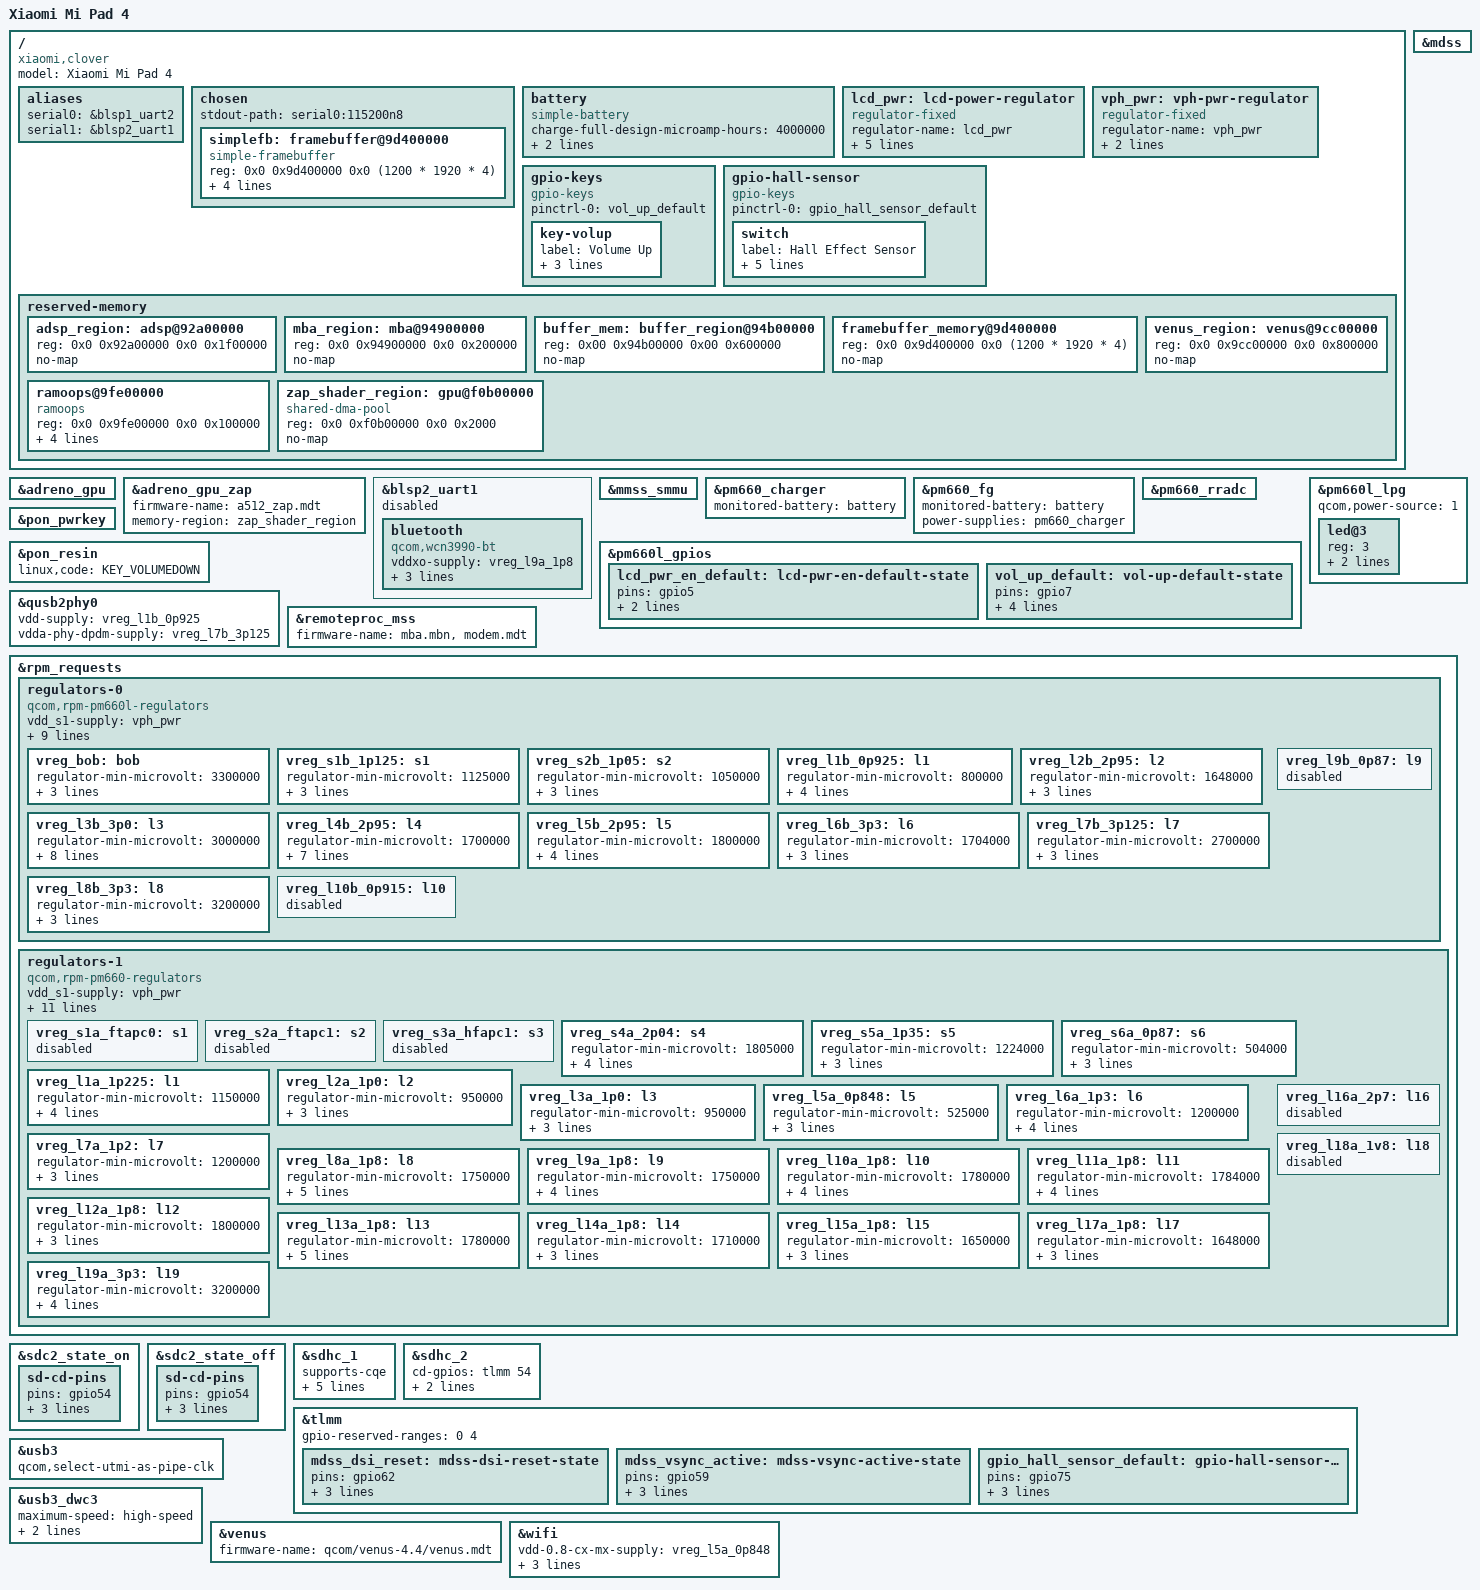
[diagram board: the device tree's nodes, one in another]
// SPDX-License-Identifier: GPL-2.0-only
/*
 * Copyright (c) 2020, Mark Hargreaves <clashclanacc2602@gmail.com>
 */

/dts-v1/;
#include "sdm660.dtsi"
#include "pm660.dtsi"
#include "pm660l.dtsi"
#include <dt-bindings/input/input.h>
#include <dt-bindings/input/gpio-keys.h>
#include <dt-bindings/leds/common.h>
#include <dt-bindings/pinctrl/qcom,pmic-gpio.h>

/delete-node/ &adsp_region;
/delete-node/ &buffer_mem;
/delete-node/ &mba_region;
/delete-node/ &zap_shader_region;
/delete-node/ &venus_region;

/ {
	/*
	 * This DT does not handle differences between Mi PAD 4 and Mi PAD 4 PLUS.
	 * This is commonized DTS contaning only subset of features between both
	 * xiaomi-clover and xiaomi-clover-plus needed for u-boot to function.
	 */
	model = "Xiaomi Mi Pad 4";
	compatible = "xiaomi,clover", "qcom,sdm660";

	aliases {
		serial0 = &blsp1_uart2; /* Debug UART */
		serial1 = &blsp2_uart1; /* Bluetooth UART */
	};

	chosen {
		#address-cells = <2>;
		#size-cells = <2>;
		ranges;

		stdout-path = "serial0:115200n8";

		/*
		 * Despite screen physical size is different between clover and
		 * clover-plus, the resolution is the same.
		 */
		simplefb: framebuffer@9d400000 {
			compatible = "simple-framebuffer";
			reg = <0x0 0x9d400000 0x0 (1200 * 1920 * 4)>;
			width = <1200>;
			height = <1920>;
			stride = <(1200 * 4)>;
			format = "a8r8g8b8";
		};
	};

	battery: battery {
		compatible = "simple-battery";

		charge-full-design-microamp-hours = <4000000>;
		voltage-min-design-microvolt = <3400000>;
		voltage-max-design-microvolt = <4408000>;
	};

	lcd_pwr: lcd-power-regulator {
		compatible = "regulator-fixed";
		regulator-name = "lcd_pwr";
		regulator-min-microvolt = <3300000>;
		regulator-max-microvolt = <3300000>;
		gpio = <&pm660l_gpios 5 GPIO_ACTIVE_HIGH>;
		enable-active-high;
		pinctrl-0 = <&lcd_pwr_en_default>;
		pinctrl-names = "default";
	};

	vph_pwr: vph-pwr-regulator {
		compatible = "regulator-fixed";
		regulator-name = "vph_pwr";

		regulator-always-on;
		regulator-boot-on;
	};

	gpio-keys {
		compatible = "gpio-keys";

		pinctrl-0 = <&vol_up_default>;
		pinctrl-names = "default";

		key-volup {
			label = "Volume Up";
			gpios = <&pm660l_gpios 7 GPIO_ACTIVE_LOW>;
			linux,code = <KEY_VOLUMEUP>;
			debounce-interval = <15>;
		};
	};

	gpio-hall-sensor {
		compatible = "gpio-keys";

		pinctrl-0 = <&gpio_hall_sensor_default>;
		pinctrl-names = "default";

		switch {
			label = "Hall Effect Sensor";
			gpios = <&tlmm 75 GPIO_ACTIVE_LOW>;
			linux,input-type = <EV_SW>;
			linux,code = <SW_LID>;
			linux,can-disable;
			wakeup-source;
		};
	};

	reserved-memory {
		#address-cells = <2>;
		#size-cells = <2>;
		ranges;

		adsp_region: adsp@92a00000 {
			reg = <0x0 0x92a00000 0x0 0x1f00000>;
			no-map;
		};

		mba_region: mba@94900000 {
			reg = <0x0 0x94900000 0x0 0x200000>;
			no-map;
		};

		buffer_mem: buffer_region@94b00000 {
			reg = <0x00 0x94b00000 0x00 0x600000>;
			no-map;
		};

		framebuffer_memory@9d400000 {
			reg = <0x0 0x9d400000 0x0 (1200 * 1920 * 4)>;
			no-map;
		};

		venus_region: venus@9cc00000 {
			reg = <0x0 0x9cc00000 0x0 0x800000>;
			no-map;
		};

		ramoops@9fe00000 {
			compatible = "ramoops";
			reg = <0x0 0x9fe00000 0x0 0x100000>;
			console-size = <0x80000>;
			record-size = <0x1000>;
			ftrace-size = <0x1000>;
			pmsg-size = <0x8000>;
		};

		zap_shader_region: gpu@f0b00000 {
			compatible = "shared-dma-pool";
			reg = <0x0 0xf0b00000 0x0 0x2000>;
			no-map;
		};

	};
};

&adreno_gpu {
	status = "okay";
};

&adreno_gpu_zap {
	firmware-name = "a512_zap.mdt";
	memory-region = <&zap_shader_region>;
};

&blsp2_uart1 {
	/* status = "okay"; Do not enable bluetooth UART, this confuses U-Boot */
	/* we build u-boot for clover without CONFIG_SERIAL_PRESENT */
	status = "disabled";

	bluetooth {
		compatible = "qcom,wcn3990-bt";
		vddxo-supply = <&vreg_l9a_1p8>;
		vddrf-supply = <&vreg_l6a_1p3>;
		vddch0-supply = <&vreg_l19a_3p3>;
		max-speed = <3200000>;
	};
};

&mdss {
	status = "okay";
};

&mmss_smmu {
	status = "okay";
};

&pm660_charger {
	monitored-battery = <&battery>;

	status = "okay";
};

&pm660_fg {
	monitored-battery = <&battery>;
	power-supplies = <&pm660_charger>;

	status = "okay";
};

&pm660_rradc {
	status = "okay";
};

&pm660l_gpios {
	lcd_pwr_en_default: lcd-pwr-en-default-state {
		pins = "gpio5";
		function = PMIC_GPIO_FUNC_NORMAL;
		bias-disable;
	};

	vol_up_default: vol-up-default-state {
		pins = "gpio7";
		function = PMIC_GPIO_FUNC_NORMAL;
		bias-pull-up;
		input-enable;
		qcom,drive-strength = <PMIC_GPIO_STRENGTH_NO>;
	};
};

&pm660l_lpg {
	qcom,power-source = <1>;

	status = "okay";

	#address-cells = <1>;
	#size-cells = <0>;

	led@3 {
		reg = <3>;
		color = <LED_COLOR_ID_WHITE>;
		function = LED_FUNCTION_STATUS;
	};
};

&pon_pwrkey {
	status = "okay";
};

&pon_resin {
	linux,code = <KEY_VOLUMEDOWN>;

	status = "okay";
};

&qusb2phy0 {
	vdd-supply = <&vreg_l1b_0p925>;
	vdda-phy-dpdm-supply = <&vreg_l7b_3p125>;

	status = "okay";
};

&remoteproc_mss {
	firmware-name = "mba.mbn", "modem.mdt";

	status = "okay";
};

&rpm_requests {
	regulators-0 {
		compatible = "qcom,rpm-pm660l-regulators";

		vdd_s1-supply = <&vph_pwr>;
		vdd_s2-supply = <&vph_pwr>;
		vdd_s3_s4-supply = <&vph_pwr>;
		vdd_s5-supply = <&vph_pwr>;
		vdd_s6-supply = <&vph_pwr>;

		vdd_l1_l9_l10-supply = <&vreg_s2b_1p05>;
		vdd_l2-supply = <&vreg_bob>;
		vdd_l3_l5_l7_l8-supply = <&vreg_bob>;
		vdd_l4_l6-supply = <&vreg_bob>;
		vdd_bob-supply = <&vph_pwr>;

		vreg_bob: bob {
			regulator-min-microvolt = <3300000>;
			regulator-max-microvolt = <3600000>;
			regulator-enable-ramp-delay = <500>;
			regulator-ramp-delay = <0>;
		};

		vreg_s1b_1p125: s1 {
			regulator-min-microvolt = <1125000>;
			regulator-max-microvolt = <1125000>;
			regulator-enable-ramp-delay = <200>;
			regulator-ramp-delay = <0>;
		};

		vreg_s2b_1p05: s2 {
			regulator-min-microvolt = <1050000>;
			regulator-max-microvolt = <1050000>;
			regulator-enable-ramp-delay = <200>;
			regulator-ramp-delay = <0>;
		};

		/* LDOs */
		vreg_l1b_0p925: l1 {
			regulator-min-microvolt = <800000>;
			regulator-max-microvolt = <925000>;
			regulator-enable-ramp-delay = <250>;
			regulator-ramp-delay = <0>;
			regulator-allow-set-load;
		};

		/* SDHCI 3.3V signal doesn't seem to be supported. */
		vreg_l2b_2p95: l2 {
			regulator-min-microvolt = <1648000>;
			regulator-max-microvolt = <3100000>;
			regulator-enable-ramp-delay = <250>;
			regulator-allow-set-load;
		};

		vreg_l3b_3p0: l3 {
			regulator-min-microvolt = <3000000>;
			regulator-max-microvolt = <3000000>;
			regulator-enable-ramp-delay = <250>;
			regulator-ramp-delay = <0>;
			regulator-min-microamp = <200>;
			regulator-max-microamp = <600000>;
			regulator-system-load = <100000>;
			regulator-allow-set-load;
			regulator-always-on;
		};

		vreg_l4b_2p95: l4 {
			regulator-min-microvolt = <1700000>;
			regulator-max-microvolt = <2952000>;
			regulator-enable-ramp-delay = <250>;
			regulator-ramp-delay = <0>;

			regulator-min-microamp = <200>;
			regulator-max-microamp = <600000>;
			regulator-system-load = <570000>;
			regulator-allow-set-load;
		};

		/*
		 * Downstream specifies a range of 1721-3600mV,
		 * but the only assigned consumers are SDHCI2 VMMC
		 * and Coresight QPDI that both request pinned 2.95V.
		 * Tighten the range to 1.8-3.328 (closest to 3.3) to
		 * make the mmc driver happy.
		 */
		vreg_l5b_2p95: l5 {
			regulator-min-microvolt = <1800000>;
			regulator-max-microvolt = <3328000>;
			regulator-enable-ramp-delay = <250>;
			regulator-ramp-delay = <0>;
			regulator-allow-set-load;
		};

		vreg_l6b_3p3: l6 {
			regulator-min-microvolt = <1704000>;
			regulator-max-microvolt = <3312000>;
			regulator-enable-ramp-delay = <250>;
			regulator-ramp-delay = <0>;
		};

		vreg_l7b_3p125: l7 {
			regulator-min-microvolt = <2700000>;
			regulator-max-microvolt = <3125000>;
			regulator-enable-ramp-delay = <250>;
			regulator-ramp-delay = <0>;
		};

		vreg_l8b_3p3: l8 {
			regulator-min-microvolt = <3200000>;
			regulator-max-microvolt = <3400000>;
			regulator-enable-ramp-delay = <250>;
			regulator-ramp-delay = <0>;
		};

		vreg_l9b_0p87: l9 {
			/* Unused */
			status = "disabled";
		};

		vreg_l10b_0p915: l10 {
			/* Unused */
			status = "disabled";
		};
	};

	regulators-1 {
		compatible = "qcom,rpm-pm660-regulators";

		vdd_s1-supply = <&vph_pwr>;
		vdd_s2-supply = <&vph_pwr>;
		vdd_s3-supply = <&vph_pwr>;
		vdd_s4-supply = <&vph_pwr>;
		vdd_s5-supply = <&vph_pwr>;
		vdd_s6-supply = <&vph_pwr>;

		vdd_l1_l6_l7-supply = <&vreg_s5a_1p35>;
		vdd_l2_l3-supply = <&vreg_s2b_1p05>;
		vdd_l5-supply = <&vreg_s2b_1p05>;
		vdd_l8_l9_l10_l11_l12_l13_l14-supply = <&vreg_s4a_2p04>;
		vdd_l15_l16_l17_l18_l19-supply = <&vreg_bob>;

		vreg_s1a_ftapc0: s1 {
			/* Unused */
			status = "disabled";
		};

		vreg_s2a_ftapc1: s2 {
			/* Unused */
			status = "disabled";
		};

		vreg_s3a_hfapc1: s3 {
			/* Unused */
			status = "disabled";
		};

		vreg_s4a_2p04: s4 {
			regulator-min-microvolt = <1805000>;
			regulator-max-microvolt = <2040000>;
			regulator-enable-ramp-delay = <200>;
			regulator-ramp-delay = <0>;
			regulator-always-on;
		};

		vreg_s5a_1p35: s5 {
			regulator-min-microvolt = <1224000>;
			regulator-max-microvolt = <1350000>;
			regulator-enable-ramp-delay = <200>;
			regulator-ramp-delay = <0>;
		};

		vreg_s6a_0p87: s6 {
			regulator-min-microvolt = <504000>;
			regulator-max-microvolt = <992000>;
			regulator-enable-ramp-delay = <150>;
			regulator-ramp-delay = <0>;
		};

		/* LDOs */
		vreg_l1a_1p225: l1 {
			regulator-min-microvolt = <1150000>;
			regulator-max-microvolt = <1250000>;
			regulator-enable-ramp-delay = <250>;
			regulator-ramp-delay = <0>;
			regulator-allow-set-load;
			/* regulator-always-on; */
		};

		vreg_l2a_1p0: l2 {
			regulator-min-microvolt = <950000>;
			regulator-max-microvolt = <1010000>;
			regulator-enable-ramp-delay = <250>;
			regulator-ramp-delay = <0>;
		};

		vreg_l3a_1p0: l3 {
			regulator-min-microvolt = <950000>;
			regulator-max-microvolt = <1010000>;
			regulator-enable-ramp-delay = <250>;
			regulator-ramp-delay = <0>;
		};

		vreg_l5a_0p848: l5 {
			regulator-min-microvolt = <525000>;
			regulator-max-microvolt = <952000>;
			regulator-enable-ramp-delay = <250>;
			regulator-ramp-delay = <0>;
		};

		vreg_l6a_1p3: l6 {
			regulator-min-microvolt = <1200000>;
			regulator-max-microvolt = <1368000>;
			regulator-allow-set-load;
			regulator-enable-ramp-delay = <250>;
			regulator-ramp-delay = <0>;
		};

		vreg_l7a_1p2: l7 {
			regulator-min-microvolt = <1200000>;
			regulator-max-microvolt = <1200000>;
			regulator-enable-ramp-delay = <250>;
			regulator-ramp-delay = <0>;
		};

		vreg_l8a_1p8: l8 {
			regulator-min-microvolt = <1750000>;
			regulator-max-microvolt = <1900000>;
			regulator-enable-ramp-delay = <250>;
			regulator-ramp-delay = <0>;
			regulator-system-load = <325000>;
			regulator-allow-set-load;
		};


		vreg_l9a_1p8: l9 {
			regulator-min-microvolt = <1750000>;
			regulator-max-microvolt = <1900000>;
			regulator-enable-ramp-delay = <250>;
			regulator-ramp-delay = <0>;
			regulator-allow-set-load;
		};

		vreg_l10a_1p8: l10 {
			regulator-min-microvolt = <1780000>;
			regulator-max-microvolt = <1950000>;
			regulator-enable-ramp-delay = <250>;
			regulator-ramp-delay = <0>;
			regulator-allow-set-load;
		};

		vreg_l11a_1p8: l11 {
			regulator-min-microvolt = <1784000>;
			regulator-max-microvolt = <1944000>;
			regulator-enable-ramp-delay = <250>;
			regulator-ramp-delay = <0>;
			regulator-always-on;
		};

		vreg_l12a_1p8: l12 {
			regulator-min-microvolt = <1800000>;
			regulator-max-microvolt = <1944000>;
			regulator-enable-ramp-delay = <250>;
			regulator-ramp-delay = <0>;
		};

		/* This gives power to the LPDDR4: never turn it off! */
		vreg_l13a_1p8: l13 {
			regulator-min-microvolt = <1780000>;
			regulator-max-microvolt = <1950000>;
			regulator-enable-ramp-delay = <250>;
			regulator-ramp-delay = <0>;
			regulator-boot-on;
			regulator-always-on;
		};

		vreg_l14a_1p8: l14 {
			regulator-min-microvolt = <1710000>;
			regulator-max-microvolt = <1904000>;
			regulator-enable-ramp-delay = <250>;
			regulator-ramp-delay = <0>;
		};

		vreg_l15a_1p8: l15 {
			regulator-min-microvolt = <1650000>;
			regulator-max-microvolt = <2952000>;
			regulator-enable-ramp-delay = <250>;
			regulator-ramp-delay = <0>;
		};

		vreg_l16a_2p7: l16 {
			/* Unused */
			status = "disabled";
		};

		vreg_l17a_1p8: l17 {
			regulator-min-microvolt = <1648000>;
			regulator-max-microvolt = <2952000>;
			regulator-enable-ramp-delay = <250>;
			regulator-ramp-delay = <0>;
		};

		vreg_l18a_1v8: l18 {
			status = "disabled";
		};

		vreg_l19a_3p3: l19 {
			regulator-min-microvolt = <3200000>;
			regulator-max-microvolt = <3400000>;
			regulator-enable-ramp-delay = <250>;
			regulator-ramp-delay = <0>;
			regulator-allow-set-load;
		};
	};
};

&sdc2_state_on {
	sd-cd-pins {
		pins = "gpio54";
		function = "gpio";
		bias-pull-up;
		drive-strength = <2>;
	};
};

&sdc2_state_off {
	sd-cd-pins {
		pins = "gpio54";
		function = "gpio";
		bias-disable;
		drive-strength = <2>;
	};
};

&sdhc_1 {
	supports-cqe;

	mmc-hs200-1_8v;
	mmc-hs400-1_8v;
	mmc-hs400-enhanced-strobe;

	vmmc-supply = <&vreg_l4b_2p95>;
	vqmmc-supply = <&vreg_l8a_1p8>;

	status = "okay";
};

&sdhc_2 {
	cd-gpios = <&tlmm 54 GPIO_ACTIVE_HIGH>;

	vmmc-supply = <&vreg_l5b_2p95>;
	vqmmc-supply = <&vreg_l2b_2p95>;

	status = "okay";
};

&tlmm {
	gpio-reserved-ranges = <0 4>;

	mdss_dsi_reset: mdss-dsi-reset-state {
		pins = "gpio62";
		function = "gpio";
		drive-strength = <8>;
		bias-disable;
	};

	mdss_vsync_active: mdss-vsync-active-state {
		pins = "gpio59";
		function = "mdp_vsync";
		drive-strength = <2>;
		bias-pull-down;
	};

	gpio_hall_sensor_default: gpio-hall-sensor-default-state {
		pins = "gpio75";
		function = "gpio";
		drive-strength = <6>;
		bias-pull-up;
	};
};

&usb3 {
	qcom,select-utmi-as-pipe-clk; /* Required if only USB 2.0 is available */

	status = "okay";
};

&usb3_dwc3 {
	maximum-speed = "high-speed";
	phys = <&qusb2phy0>;
	phy-names = "usb2-phy";
	dr_mode = "peripheral";

	status = "okay";
};

&venus {
	firmware-name = "qcom/venus-4.4/venus.mdt";

	status = "okay";
};

&wifi {
	vdd-0.8-cx-mx-supply = <&vreg_l5a_0p848>;
	vdd-1.8-xo-supply = <&vreg_l9a_1p8>;
	vdd-1.3-rfa-supply = <&vreg_l6a_1p3>;
	vdd-3.3-ch0-supply = <&vreg_l19a_3p3>;

	status = "okay";
};
